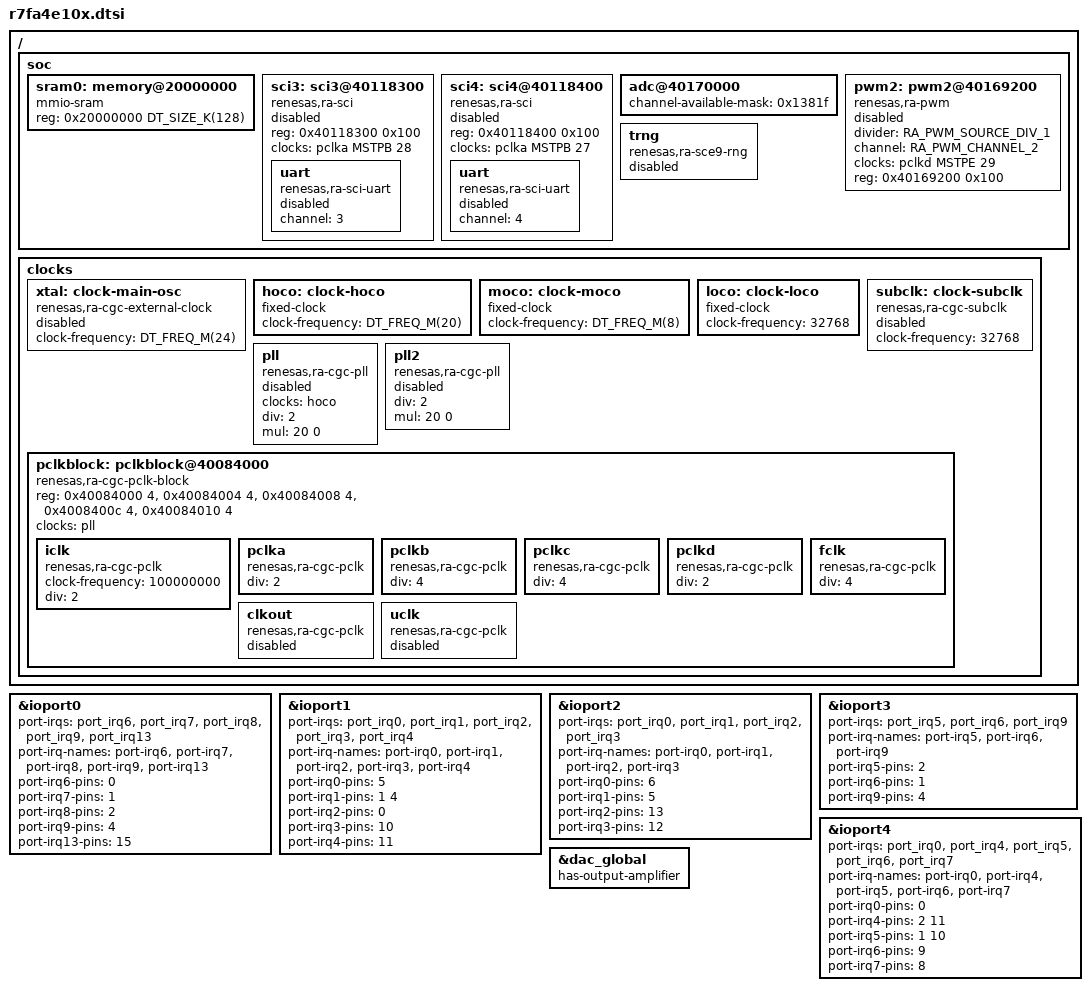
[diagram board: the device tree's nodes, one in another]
/*
 * Copyright (c) 2025 Renesas Electronics Corporation
 *
 * SPDX-License-Identifier: Apache-2.0
 */

#include <arm/renesas/ra/ra4/ra4-cm33-common.dtsi>
#include <zephyr/dt-bindings/clock/ra_clock.h>
#include <zephyr/dt-bindings/pwm/ra_pwm.h>

/delete-node/ &spi1;
/delete-node/ &agt4;
/delete-node/ &adc1;
/delete-node/ &dac1;
/delete-node/ &iic1;
/delete-node/ &pwm0;

/ {
	soc {
		sram0: memory@20000000 {
			compatible = "mmio-sram";
			reg = <0x20000000 DT_SIZE_K(128)>;
		};

		sci3: sci3@40118300 {
			compatible = "renesas,ra-sci";
			reg = <0x40118300 0x100>;
			clocks = <&pclka MSTPB 28>;
			status = "disabled";

			uart {
				compatible = "renesas,ra-sci-uart";
				channel = <3>;
				status = "disabled";
			};
		};

		sci4: sci4@40118400 {
			compatible = "renesas,ra-sci";
			reg = <0x40118400 0x100>;
			clocks = <&pclka MSTPB 27>;
			status = "disabled";

			uart {
				compatible = "renesas,ra-sci-uart";
				channel = <4>;
				status = "disabled";
			};
		};

		adc@40170000 {
			channel-available-mask = <0x1381f>;
		};

		pwm2: pwm2@40169200 {
			compatible = "renesas,ra-pwm";
			divider = <RA_PWM_SOURCE_DIV_1>;
			channel = <RA_PWM_CHANNEL_2>;
			clocks = <&pclkd MSTPE 29>;
			reg = <0x40169200 0x100>;
			#pwm-cells = <3>;
			status = "disabled";
		};

		trng: trng {
			compatible = "renesas,ra-sce9-rng";
			status = "disabled";
		};
	};

	clocks: clocks {
		#address-cells = <1>;
		#size-cells = <1>;

		xtal: clock-main-osc {
			compatible = "renesas,ra-cgc-external-clock";
			clock-frequency = <DT_FREQ_M(24)>;
			#clock-cells = <0>;
			status = "disabled";
		};

		hoco: clock-hoco {
			compatible = "fixed-clock";
			clock-frequency = <DT_FREQ_M(20)>;
			#clock-cells = <0>;
		};

		moco: clock-moco {
			compatible = "fixed-clock";
			clock-frequency = <DT_FREQ_M(8)>;
			#clock-cells = <0>;
		};

		loco: clock-loco {
			compatible = "fixed-clock";
			clock-frequency = <32768>;
			#clock-cells = <0>;
		};

		subclk: clock-subclk {
			compatible = "renesas,ra-cgc-subclk";
			clock-frequency = <32768>;
			#clock-cells = <0>;
			status = "disabled";
		};

		pll: pll {
			compatible = "renesas,ra-cgc-pll";
			#clock-cells = <0>;

			/* PLL */
			clocks = <&hoco>;
			div = <2>;
			mul = <20 0>;
			status = "disabled";
		};

		pll2: pll2 {
			compatible = "renesas,ra-cgc-pll";
			#clock-cells = <0>;

			/* PLL2 */
			div = <2>;
			mul = <20 0>;
			status = "disabled";
		};

		pclkblock: pclkblock@40084000 {
			compatible = "renesas,ra-cgc-pclk-block";
			reg = <0x40084000 4>, <0x40084004 4>, <0x40084008 4>,
			      <0x4008400c 4>, <0x40084010 4>;
			reg-names = "MSTPA", "MSTPB", "MSTPC",
				    "MSTPD", "MSTPE";
			#clock-cells = <0>;
			clocks = <&pll>;
			status = "okay";

			iclk: iclk {
				compatible = "renesas,ra-cgc-pclk";
				clock-frequency = <100000000>;
				div = <2>;
				#clock-cells = <2>;
				status = "okay";
			};

			pclka: pclka {
				compatible = "renesas,ra-cgc-pclk";
				div = <2>;
				#clock-cells = <2>;
				status = "okay";
			};

			pclkb: pclkb {
				compatible = "renesas,ra-cgc-pclk";
				div = <4>;
				#clock-cells = <2>;
				status = "okay";
			};

			pclkc: pclkc {
				compatible = "renesas,ra-cgc-pclk";
				div = <4>;
				#clock-cells = <2>;
				status = "okay";
			};

			pclkd: pclkd {
				compatible = "renesas,ra-cgc-pclk";
				div = <2>;
				#clock-cells = <2>;
				status = "okay";
			};

			fclk: fclk {
				compatible = "renesas,ra-cgc-pclk";
				div = <4>;
				#clock-cells = <2>;
				status = "okay";
			};

			clkout: clkout {
				compatible = "renesas,ra-cgc-pclk";
				#clock-cells = <2>;
				status = "disabled";
			};

			uclk: uclk {
				compatible = "renesas,ra-cgc-pclk";
				#clock-cells = <2>;
				status = "disabled";
			};
		};
	};
};

&ioport0 {
	port-irqs = <&port_irq6 &port_irq7 &port_irq8
	&port_irq9 &port_irq13>;
	port-irq-names = "port-irq6",
			 "port-irq7",
			 "port-irq8",
			 "port-irq9",
			 "port-irq13";
	port-irq6-pins = <0>;
	port-irq7-pins = <1>;
	port-irq8-pins = <2>;
	port-irq9-pins = <4>;
	port-irq13-pins = <15>;
};

&ioport1 {
	port-irqs = <&port_irq0 &port_irq1 &port_irq2
	&port_irq3 &port_irq4>;
	port-irq-names = "port-irq0",
			 "port-irq1",
			 "port-irq2",
			 "port-irq3",
			 "port-irq4";
	port-irq0-pins = <5>;
	port-irq1-pins = <1 4>;
	port-irq2-pins = <0>;
	port-irq3-pins = <10>;
	port-irq4-pins = <11>;
};

&ioport2 {
	port-irqs = <&port_irq0 &port_irq1 &port_irq2
	&port_irq3>;
	port-irq-names = "port-irq0",
			 "port-irq1",
			 "port-irq2",
			 "port-irq3";
	port-irq0-pins = <6>;
	port-irq1-pins = <5>;
	port-irq2-pins = <13>;
	port-irq3-pins = <12>;
};

&ioport3 {
	port-irqs = <&port_irq5 &port_irq6 &port_irq9>;
	port-irq-names = "port-irq5",
			 "port-irq6",
			 "port-irq9";
	port-irq5-pins = <2>;
	port-irq6-pins = <1>;
	port-irq9-pins = <4>;
};

&ioport4 {
	port-irqs = <&port_irq0 &port_irq4 &port_irq5
	&port_irq6 &port_irq7>;
	port-irq-names = "port-irq0",
			 "port-irq4",
			 "port-irq5",
			 "port-irq6",
			 "port-irq7";
	port-irq0-pins = <0>;
	port-irq4-pins = <2 11>;
	port-irq5-pins = <1 10>;
	port-irq6-pins = <9>;
	port-irq7-pins = <8>;
};

&dac_global {
	has-output-amplifier;
};
